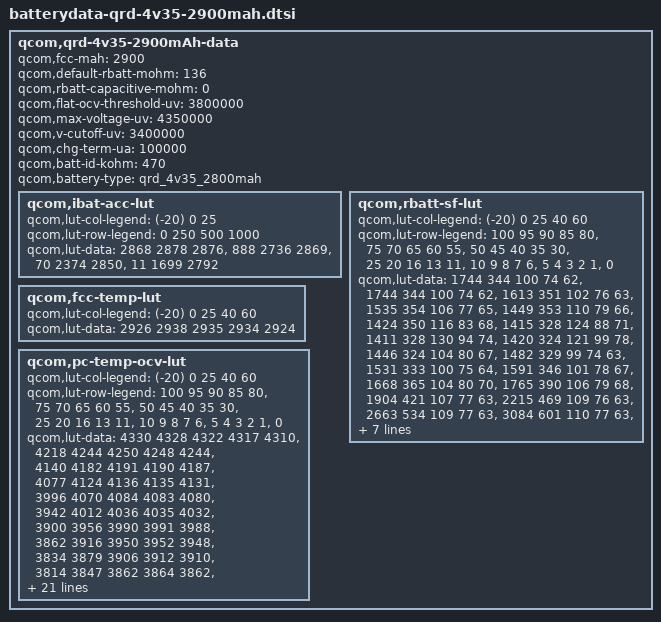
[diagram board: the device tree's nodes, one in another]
/* Copyright (c) 2013, The Linux Foundation. All rights reserved.
 *
 * This program is free software; you can redistribute it and/or modify
 * it under the terms of the GNU General Public License version 2 and
 * only version 2 as published by the Free Software Foundation.
 *
 * This program is distributed in the hope that it will be useful,
 * but WITHOUT ANY WARRANTY; without even the implied warranty of
 * MERCHANTABILITY or FITNESS FOR A PARTICULAR PURPOSE.  See the
 * GNU General Public License for more details.
 */

qcom,qrd-4v35-2900mAh-data {
	qcom,fcc-mah = <2900>;
	qcom,default-rbatt-mohm = <136>;
	qcom,rbatt-capacitive-mohm = <0>;
	qcom,flat-ocv-threshold-uv = <3800000>;
	qcom,max-voltage-uv = <4350000>;
	qcom,v-cutoff-uv = <3400000>;
	qcom,chg-term-ua = <100000>;
	qcom,batt-id-kohm = <470>;
	qcom,battery-type = "qrd_4v35_2800mah";
  
  
  qcom,ibat-acc-lut {
		qcom,lut-col-legend = <(-20) 0 25>;
		qcom,lut-row-legend = <0 250 500 1000>;
		qcom,lut-data = <2868 2878 2876>,
		                <888 2736 2869>,
		                <70 2374 2850>,
		                <11 1699 2792>;
	};

	qcom,rbatt-sf-lut {
		qcom,lut-col-legend = <(-20) 0 25 40 60>;
		qcom,lut-row-legend = <100 95 90 85 80>,
				      <75 70 65 60 55>, 
				      <50 45 40 35 30>,
				      <25 20 16 13 11>,
				      <10 9 8 7 6>, 
				      <5 4 3 2 1>,
				      <0>;
		qcom,lut-data = <1744 344 100 74 62>,
				<1744 344 100 74 62>,
				<1613 351 102 76 63>, 
				<1535 354 106 77 65>, 
				<1449 353 110 79 66>, 
				<1424 350 116 83 68>, 
				<1415 328 124 88 71>, 
				<1411 328 130 94 74>, 
				<1420 324 121 99 78>, 
				<1446 324 104 80 67>, 
				<1482 329 99 74 63>, 
				<1531 333 100 75 64>, 
				<1591 346 101 78 67>, 
				<1668 365 104 80 70>, 
				<1765 390 106 79 68>, 
				<1904 421 107 77 63>, 
				<2215 469 109 76 63>, 
				<2663 534 109 77 63>, 
				<3084 601 110 77 63>, 
				<3101 615 109 76 64>, 
				<3303 642 112 79 65>, 
				<3638 679 115 81 67>, 
				<4074 724 121 83 69>, 
				<4601 775 128 87 71>, 
				<5278 834 135 90 72>, 
				<6223 900 138 88 68>, 
				<7572 981 136 85 68>, 
				<9818 1091 145 90 71>, 
				<14279 1338 163 99 77>, 
				<25400 2675 326 197 106>, 
				<50800 5350 653 394 212>;
	};

	qcom,fcc-temp-lut {
		qcom,lut-col-legend = <(-20) 0 25 40 60>;
		qcom,lut-data = <2926 2938 2935 2934 2924>;     
	};

	qcom,pc-temp-ocv-lut {
		qcom,lut-col-legend = <(-20) 0 25 40 60>;
		qcom,lut-row-legend = <100 95 90 85 80>,    
				<75 70 65 60 55>,
				<50 45 40 35 30>,
				<25 20 16 13 11>,
				<10 9 8 7 6>,
				<5 4 3 2 1>,
                <0>;
		qcom,lut-data = 
		         <4330 4328 4322 4317 4310>,
				 <4218 4244 4250 4248 4244>, 
				 <4140 4182 4191 4190 4187>, 
				 <4077 4124 4136 4135 4131>, 
				 <3996 4070 4084 4083 4080>, 
				 <3942 4012 4036 4035 4032>, 
				 <3900 3956 3990 3991 3988>, 
				 <3862 3916 3950 3952 3948>, 
				 <3834 3879 3906 3912 3910>, 
				 <3814 3847 3862 3864 3862>, 
				 <3798 3820 3832 3832 3832>, 
				 <3783 3798 3810 3810 3809>, 
				 <3768 3782 3791 3792 3791>, 
				 <3752 3770 3777 3777 3776>, 
				 <3734 3757 3765 3762 3758>, 
				 <3714 3740 3752 3746 3734>, 
				 <3688 3720 3734 3726 3712>, 
				 <3664 3703 3710 3702 3690>, 
				 <3640 3690 3688 3680 3668>, 
				 <3625 3681 3678 3672 3661>, 
				 <3614 3675 3676 3670 3659>, 
				 <3602 3669 3673 3668 3657>, 
				 <3587 3662 3670 3665 3654>, 
				 <3571 3652 3666 3662 3650>, 
				 <3550 3638 3657 3654 3640>, 
				 <3524 3613 3637 3632 3612>, 
				 <3492 3573 3591 3582 3566>, 
				 <3446 3512 3526 3518 3502>, 
				 <3378 3417 3436 3429 3414>, 
				 <3260 3262 3298 3290 3282>, 
				 <3006 3000 3000 3000 3000>;
	};                               
};
